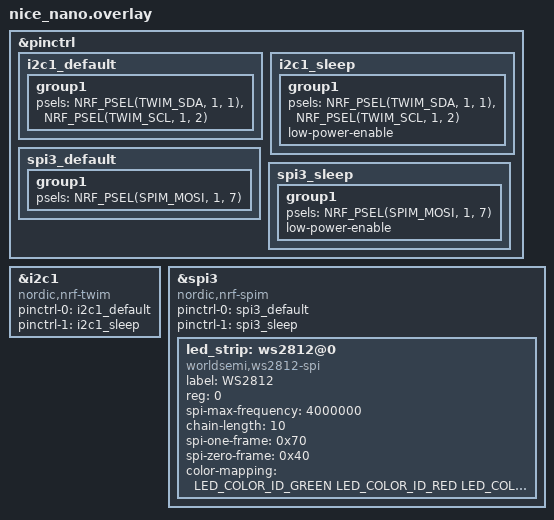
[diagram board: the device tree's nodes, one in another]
/*
 * Copyright (c) 2024 The ZMK Contributors
 * SPDX-License-Identifier: MIT
 */

/* Pinctrl definitions for I2C1 (Trackball) */
&pinctrl {
    i2c1_default: i2c1_default {
        group1 {
            psels = <NRF_PSEL(TWIM_SDA, 1, 1)>,  /* P1.01 (Extra GPIO) */
                    <NRF_PSEL(TWIM_SCL, 1, 2)>;  /* P1.02 (Extra GPIO) */
        };
    };

    i2c1_sleep: i2c1_sleep {
        group1 {
            psels = <NRF_PSEL(TWIM_SDA, 1, 1)>,
                    <NRF_PSEL(TWIM_SCL, 1, 2)>;
            low-power-enable;
        };
    };

    spi3_default: spi3_default {
        group1 {
            psels = <NRF_PSEL(SPIM_MOSI, 1, 7)>;
        };
    };

    spi3_sleep: spi3_sleep {
        group1 {
            psels = <NRF_PSEL(SPIM_MOSI, 1, 7)>;
            low-power-enable;
        };
    };
};

/* I2C1 configuration for trackball using D12/D13 */
&i2c1 {
    compatible = "nordic,nrf-twim";
    status = "okay";
    pinctrl-0 = <&i2c1_default>;
    pinctrl-1 = <&i2c1_sleep>;
    pinctrl-names = "default", "sleep";
};

/* LED Strip (WS2812) on extra GPIO P1.07 */
&spi3 {
    compatible = "nordic,nrf-spim";
    status = "okay";
    pinctrl-0 = <&spi3_default>;
    pinctrl-1 = <&spi3_sleep>;
    pinctrl-names = "default", "sleep";

    led_strip: ws2812@0 {
        compatible = "worldsemi,ws2812-spi";
        label = "WS2812";
        reg = <0>;
        spi-max-frequency = <4000000>;
        chain-length = <10>;
        spi-one-frame = <0x70>;
        spi-zero-frame = <0x40>;
        color-mapping = <LED_COLOR_ID_GREEN LED_COLOR_ID_RED LED_COLOR_ID_BLUE>;
    };
};
